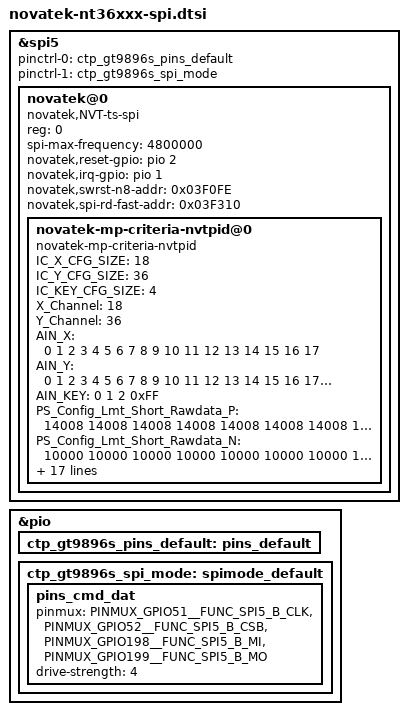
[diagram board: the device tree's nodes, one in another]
/*
 * Copyright (C) 2010 - 2018 Novatek, Inc.
 *
 * $Revision$
 * $Date$
 *
 * This program is free software; you can redistribute it and/or modify
 * it under the terms of the GNU General Public License as published by
 * the Free Software Foundation; either version 2 of the License, or
 * (at your option) any later version.
 *
 * This program is distributed in the hope that it will be useful, but WITHOUT
 * ANY WARRANTY; without even the implied warranty of MERCHANTABILITY or
 * FITNESS FOR A PARTICULAR PURPOSE.  See the GNU General Public License for
 * more details.
 *
 */

&spi5 {
	status = "okay";
	#address-cells = <1>;
	#size-cells = <0>;
	pinctrl-names = "default", "gt9896s_spi_mode";
	pinctrl-0 = <&ctp_gt9896s_pins_default>;
	pinctrl-1 = <&ctp_gt9896s_spi_mode>;
	/* Novatek device tree node */
	novatek@0 {
		compatible = "novatek,NVT-ts-spi";
		reg = <0>; //Same as CS ID
		status = "okay";
		//4800000,9600000,15000000,19200000
		spi-max-frequency = <4800000>;

		novatek,reset-gpio = <&pio 2 0x00>;
		novatek,irq-gpio = <&pio 1 0x00>;

		/* 525 */
		//novatek,swrst-n8-addr = <0x01F01A>;

		/* 672A, 525B, 675, 526 */
		novatek,swrst-n8-addr = <0x03F0FE>;
		novatek,spi-rd-fast-addr = <0x03F310>;

		/* MP */
		//novatek,mp-support-dt;

		novatek-mp-criteria-nvtpid@0 {
			#address-cells = <1>;
			#size-cells = <0>;
			compatible = "novatek-mp-criteria-nvtpid";

			/* MP Config */
			IC_X_CFG_SIZE = <18>;
			IC_Y_CFG_SIZE = <36>;
			IC_KEY_CFG_SIZE = <4>;
			X_Channel = <18>;
			Y_Channel = <36>;
			AIN_X = <0 1 2 3 4 5 6 7 8 9 10 11 12 13 14 15 16 17>;
			AIN_Y = <0 1 2 3 4 5 6 7 8 9 10 11 12 13 14 15 16 17
			18 19 20 21 22 23 24 25 26 27 28 29 30 31 32 33 34 35>;
			AIN_KEY = <0 1 2 0xFF>;

			/* MP Criteria */
			PS_Config_Lmt_Short_Rawdata_P =
			    <14008 14008 14008 14008 14008 14008 14008 14008 14008 14008 14008 14008
			    14008 14008 14008 14008 14008 14008 14008 14008 14008 14008 14008 14008
			    14008 14008 14008 14008 14008 14008 14008 14008 14008 14008 14008 14008
			    14008 14008 14008 14008 14008 14008 14008 14008 14008 14008 14008 14008
			    14008 14008 14008 14008 14008 14008 14008 14008 14008 14008 14008 14008
			    14008 14008 14008 14008 14008 14008 14008 14008 14008 14008 14008 14008
			    14008 14008 14008 14008 14008 14008 14008 14008 14008 14008 14008 14008
			    14008 14008 14008 14008 14008 14008 14008 14008 14008 14008 14008 14008
			    14008 14008 14008 14008 14008 14008 14008 14008 14008 14008 14008 14008
			    14008 14008 14008 14008 14008 14008 14008 14008 14008 14008 14008 14008
			    14008 14008 14008 14008 14008 14008 14008 14008 14008 14008 14008 14008
			    14008 14008 14008 14008 14008 14008 14008 14008 14008 14008 14008 14008
			    14008 14008 14008 14008 14008 14008 14008 14008 14008 14008 14008 14008
			    14008 14008 14008 14008 14008 14008 14008 14008 14008 14008 14008 14008
			    14008 14008 14008 14008 14008 14008 14008 14008 14008 14008 14008 14008
			    14008 14008 14008 14008 14008 14008 14008 14008 14008 14008 14008 14008
			    14008 14008 14008 14008 14008 14008 14008 14008 14008 14008 14008 14008
			    14008 14008 14008 14008 14008 14008 14008 14008 14008 14008 14008 14008
			    14008 14008 14008 14008 14008 14008 14008 14008 14008 14008 14008 14008
			    14008 14008 14008 14008 14008 14008 14008 14008 14008 14008 14008 14008
			    14008 14008 14008 14008 14008 14008 14008 14008 14008 14008 14008 14008
			    14008 14008 14008 14008 14008 14008 14008 14008 14008 14008 14008 14008
			    14008 14008 14008 14008 14008 14008 14008 14008 14008 14008 14008 14008
			    14008 14008 14008 14008 14008 14008 14008 14008 14008 14008 14008 14008
			    14008 14008 14008 14008 14008 14008 14008 14008 14008 14008 14008 14008
			    14008 14008 14008 14008 14008 14008 14008 14008 14008 14008 14008 14008
			    14008 14008 14008 14008 14008 14008 14008 14008 14008 14008 14008 14008
			    14008 14008 14008 14008 14008 14008 14008 14008 14008 14008 14008 14008
			    14008 14008 14008 14008 14008 14008 14008 14008 14008 14008 14008 14008
			    14008 14008 14008 14008 14008 14008 14008 14008 14008 14008 14008 14008
			    14008 14008 14008 14008 14008 14008 14008 14008 14008 14008 14008 14008
			    14008 14008 14008 14008 14008 14008 14008 14008 14008 14008 14008 14008
			    14008 14008 14008 14008 14008 14008 14008 14008 14008 14008 14008 14008
			    14008 14008 14008 14008 14008 14008 14008 14008 14008 14008 14008 14008
			    14008 14008 14008 14008 14008 14008 14008 14008 14008 14008 14008 14008
			    14008 14008 14008 14008 14008 14008 14008 14008 14008 14008 14008 14008
			    14008 14008 14008 14008 14008 14008 14008 14008 14008 14008 14008 14008
			    14008 14008 14008 14008 14008 14008 14008 14008 14008 14008 14008 14008
			    14008 14008 14008 14008 14008 14008 14008 14008 14008 14008 14008 14008
			    14008 14008 14008 14008 14008 14008 14008 14008 14008 14008 14008 14008
			    14008 14008 14008 14008 14008 14008 14008 14008 14008 14008 14008 14008
			    14008 14008 14008 14008 14008 14008 14008 14008 14008 14008 14008 14008
			    14008 14008 14008 14008 14008 14008 14008 14008 14008 14008 14008 14008
			    14008 14008 14008 14008 14008 14008 14008 14008 14008 14008 14008 14008
			    14008 14008 14008 14008 14008 14008 14008 14008 14008 14008 14008 14008
			    14008 14008 14008 14008 14008 14008 14008 14008 14008 14008 14008 14008
			    14008 14008 14008 14008 14008 14008 14008 14008 14008 14008 14008 14008
			    14008 14008 14008 14008 14008 14008 14008 14008 14008 14008 14008 14008
			    14008 14008 14008 14008 14008 14008 14008 14008 14008 14008 14008 14008
			    14008 14008 14008 14008 14008 14008 14008 14008 14008 14008 14008 14008
			    14008 14008 14008 14008 14008 14008 14008 14008 14008 14008 14008 14008
			    14008 14008 14008 14008 14008 14008 14008 14008 14008 14008 14008 14008
			    14008 14008 14008 14008 14008 14008 14008 14008 14008 14008 14008 14008
			    14008 14008 14008 14008 14008 14008 14008 14008 14008 14008 14008 14008
			    14008 14008 14008>;

			PS_Config_Lmt_Short_Rawdata_N =
			    <10000 10000 10000 10000 10000 10000 10000 10000 10000 10000 10000 10000
			    10000 10000 10000 10000 10000 10000 10000 10000 10000 10000 10000 10000
			    10000 10000 10000 10000 10000 10000 10000 10000 10000 10000 10000 10000
			    10000 10000 10000 10000 10000 10000 10000 10000 10000 10000 10000 10000
			    10000 10000 10000 10000 10000 10000 10000 10000 10000 10000 10000 10000
			    10000 10000 10000 10000 10000 10000 10000 10000 10000 10000 10000 10000
			    10000 10000 10000 10000 10000 10000 10000 10000 10000 10000 10000 10000
			    10000 10000 10000 10000 10000 10000 10000 10000 10000 10000 10000 10000
			    10000 10000 10000 10000 10000 10000 10000 10000 10000 10000 10000 10000
			    10000 10000 10000 10000 10000 10000 10000 10000 10000 10000 10000 10000
			    10000 10000 10000 10000 10000 10000 10000 10000 10000 10000 10000 10000
			    10000 10000 10000 10000 10000 10000 10000 10000 10000 10000 10000 10000
			    10000 10000 10000 10000 10000 10000 10000 10000 10000 10000 10000 10000
			    10000 10000 10000 10000 10000 10000 10000 10000 10000 10000 10000 10000
			    10000 10000 10000 10000 10000 10000 10000 10000 10000 10000 10000 10000
			    10000 10000 10000 10000 10000 10000 10000 10000 10000 10000 10000 10000
			    10000 10000 10000 10000 10000 10000 10000 10000 10000 10000 10000 10000
			    10000 10000 10000 10000 10000 10000 10000 10000 10000 10000 10000 10000
			    10000 10000 10000 10000 10000 10000 10000 10000 10000 10000 10000 10000
			    10000 10000 10000 10000 10000 10000 10000 10000 10000 10000 10000 10000
			    10000 10000 10000 10000 10000 10000 10000 10000 10000 10000 10000 10000
			    10000 10000 10000 10000 10000 10000 10000 10000 10000 10000 10000 10000
			    10000 10000 10000 10000 10000 10000 10000 10000 10000 10000 10000 10000
			    10000 10000 10000 10000 10000 10000 10000 10000 10000 10000 10000 10000
			    10000 10000 10000 10000 10000 10000 10000 10000 10000 10000 10000 10000
			    10000 10000 10000 10000 10000 10000 10000 10000 10000 10000 10000 10000
			    10000 10000 10000 10000 10000 10000 10000 10000 10000 10000 10000 10000
			    10000 10000 10000 10000 10000 10000 10000 10000 10000 10000 10000 10000
			    10000 10000 10000 10000 10000 10000 10000 10000 10000 10000 10000 10000
			    10000 10000 10000 10000 10000 10000 10000 10000 10000 10000 10000 10000
			    10000 10000 10000 10000 10000 10000 10000 10000 10000 10000 10000 10000
			    10000 10000 10000 10000 10000 10000 10000 10000 10000 10000 10000 10000
			    10000 10000 10000 10000 10000 10000 10000 10000 10000 10000 10000 10000
			    10000 10000 10000 10000 10000 10000 10000 10000 10000 10000 10000 10000
			    10000 10000 10000 10000 10000 10000 10000 10000 10000 10000 10000 10000
			    10000 10000 10000 10000 10000 10000 10000 10000 10000 10000 10000 10000
			    10000 10000 10000 10000 10000 10000 10000 10000 10000 10000 10000 10000
			    10000 10000 10000 10000 10000 10000 10000 10000 10000 10000 10000 10000
			    10000 10000 10000 10000 10000 10000 10000 10000 10000 10000 10000 10000
			    10000 10000 10000 10000 10000 10000 10000 10000 10000 10000 10000 10000
			    10000 10000 10000 10000 10000 10000 10000 10000 10000 10000 10000 10000
			    10000 10000 10000 10000 10000 10000 10000 10000 10000 10000 10000 10000
			    10000 10000 10000 10000 10000 10000 10000 10000 10000 10000 10000 10000
			    10000 10000 10000 10000 10000 10000 10000 10000 10000 10000 10000 10000
			    10000 10000 10000 10000 10000 10000 10000 10000 10000 10000 10000 10000
			    10000 10000 10000 10000 10000 10000 10000 10000 10000 10000 10000 10000
			    10000 10000 10000 10000 10000 10000 10000 10000 10000 10000 10000 10000
			    10000 10000 10000 10000 10000 10000 10000 10000 10000 10000 10000 10000
			    10000 10000 10000 10000 10000 10000 10000 10000 10000 10000 10000 10000
			    10000 10000 10000 10000 10000 10000 10000 10000 10000 10000 10000 10000
			    10000 10000 10000 10000 10000 10000 10000 10000 10000 10000 10000 10000
			    10000 10000 10000 10000 10000 10000 10000 10000 10000 10000 10000 10000
			    10000 10000 10000 10000 10000 10000 10000 10000 10000 10000 10000 10000
			    10000 10000 10000 10000 10000 10000 10000 10000 10000 10000 10000 10000
			    10000 10000 10000>;

			PS_Config_Lmt_Open_Rawdata_P =
			    <5120 5120 5120 5120 5120 5120 5120 5120 5120 5120 5120 5120 5120 5120
			    5120 5120 5120 5120 5120 5120 5120 5120 5120 5120 5120 5120 5120 5120
			    5120 5120 5120 5120 5120 5120 5120 5120 5120 5120 5120 5120 5120 5120
			    5120 5120 5120 5120 5120 5120 5120 5120 5120 5120 5120 5120 5120 5120
			    5120 5120 5120 5120 5120 5120 5120 5120 5120 5120 5120 5120 5120 5120
			    5120 5120 5120 5120 5120 5120 5120 5120 5120 5120 5120 5120 5120 5120
			    5120 5120 5120 5120 5120 5120 5120 5120 5120 5120 5120 5120 5120 5120
			    5120 5120 5120 5120 5120 5120 5120 5120 5120 5120 5120 5120 5120 5120
			    5120 5120 5120 5120 5120 5120 5120 5120 5120 5120 5120 5120 5120 5120
			    5120 5120 5120 5120 5120 5120 5120 5120 5120 5120 5120 5120 5120 5120
			    5120 5120 5120 5120 5120 5120 5120 5120 5120 5120 5120 5120 5120 5120
			    5120 5120 5120 5120 5120 5120 5120 5120 5120 5120 5120 5120 5120 5120
			    5120 5120 5120 5120 5120 5120 5120 5120 5120 5120 5120 5120 5120 5120
			    5120 5120 5120 5120 5120 5120 5120 5120 5120 5120 5120 5120 5120 5120
			    5120 5120 5120 5120 5120 5120 5120 5120 5120 5120 5120 5120 5120 5120
			    5120 5120 5120 5120 5120 5120 5120 5120 5120 5120 5120 5120 5120 5120
			    5120 5120 5120 5120 5120 5120 5120 5120 5120 5120 5120 5120 5120 5120
			    5120 5120 5120 5120 5120 5120 5120 5120 5120 5120 5120 5120 5120 5120
			    5120 5120 5120 5120 5120 5120 5120 5120 5120 5120 5120 5120 5120 5120
			    5120 5120 5120 5120 5120 5120 5120 5120 5120 5120 5120 5120 5120 5120
			    5120 5120 5120 5120 5120 5120 5120 5120 5120 5120 5120 5120 5120 5120
			    5120 5120 5120 5120 5120 5120 5120 5120 5120 5120 5120 5120 5120 5120
			    5120 5120 5120 5120 5120 5120 5120 5120 5120 5120 5120 5120 5120 5120
			    5120 5120 5120 5120 5120 5120 5120 5120 5120 5120 5120 5120 5120 5120
			    5120 5120 5120 5120 5120 5120 5120 5120 5120 5120 5120 5120 5120 5120
			    5120 5120 5120 5120 5120 5120 5120 5120 5120 5120 5120 5120 5120 5120
			    5120 5120 5120 5120 5120 5120 5120 5120 5120 5120 5120 5120 5120 5120
			    5120 5120 5120 5120 5120 5120 5120 5120 5120 5120 5120 5120 5120 5120
			    5120 5120 5120 5120 5120 5120 5120 5120 5120 5120 5120 5120 5120 5120
			    5120 5120 5120 5120 5120 5120 5120 5120 5120 5120 5120 5120 5120 5120
			    5120 5120 5120 5120 5120 5120 5120 5120 5120 5120 5120 5120 5120 5120
			    5120 5120 5120 5120 5120 5120 5120 5120 5120 5120 5120 5120 5120 5120
			    5120 5120 5120 5120 5120 5120 5120 5120 5120 5120 5120 5120 5120 5120
			    5120 5120 5120 5120 5120 5120 5120 5120 5120 5120 5120 5120 5120 5120
			    5120 5120 5120 5120 5120 5120 5120 5120 5120 5120 5120 5120 5120 5120
			    5120 5120 5120 5120 5120 5120 5120 5120 5120 5120 5120 5120 5120 5120
			    5120 5120 5120 5120 5120 5120 5120 5120 5120 5120 5120 5120 5120 5120
			    5120 5120 5120 5120 5120 5120 5120 5120 5120 5120 5120 5120 5120 5120
			    5120 5120 5120 5120 5120 5120 5120 5120 5120 5120 5120 5120 5120 5120
			    5120 5120 5120 5120 5120 5120 5120 5120 5120 5120 5120 5120 5120 5120
			    5120 5120 5120 5120 5120 5120 5120 5120 5120 5120 5120 5120 5120 5120
			    5120 5120 5120 5120 5120 5120 5120 5120 5120 5120 5120 5120 5120 5120
			    5120 5120 5120 5120 5120 5120 5120 5120 5120 5120 5120 5120 5120 5120
			    5120 5120 5120 5120 5120 5120 5120 5120 5120 5120 5120 5120 5120 5120
			    5120 5120 5120 5120 5120 5120 5120 5120 5120 5120 5120 5120 5120 5120
			    5120 5120 5120 5120 5120 5120 5120 5120 5120 5120 5120 5120 5120 5120
			    5120 5120 5120 5120 5120 5120 5120>;

			PS_Config_Lmt_Open_Rawdata_N =
			    <50 50 50 50 50 50 50 50 50 50 50 50 50 50 50 50 50 50 50 50 50 50 50 50
			    50 50 50 50 50 50 50 50 50 50 50 50 50 50 50 50 50 50 50 50 50 50 50 50
			    50 50 50 50 50 50 50 50 50 50 50 50 50 50 50 50 50 50 50 50 50 50 50 50
			    50 50 50 50 50 50 50 50 50 50 50 50 50 50 50 50 50 50 50 50 50 50 50 50
			    50 50 50 50 50 50 50 50 50 50 50 50 50 50 50 50 50 50 50 50 50 50 50 50
			    50 50 50 50 50 50 50 50 50 50 50 50 50 50 50 50 50 50 50 50 50 50 50 50
			    50 50 50 50 50 50 50 50 50 50 50 50 50 50 50 50 50 50 50 50 50 50 50 50
			    50 50 50 50 50 50 50 50 50 50 50 50 50 50 50 50 50 50 50 50 50 50 50 50
			    50 50 50 50 50 50 50 50 50 50 50 50 50 50 50 50 50 50 50 50 50 50 50 50
			    50 50 50 50 50 50 50 50 50 50 50 50 50 50 50 50 50 50 50 50 50 50 50 50
			    50 50 50 50 50 50 50 50 50 50 50 50 50 50 50 50 50 50 50 50 50 50 50 50
			    50 50 50 50 50 50 50 50 50 50 50 50 50 50 50 50 50 50 50 50 50 50 50 50
			    50 50 50 50 50 50 50 50 50 50 50 50 50 50 50 50 50 50 50 50 50 50 50 50
			    50 50 50 50 50 50 50 50 50 50 50 50 50 50 50 50 50 50 50 50 50 50 50 50
			    50 50 50 50 50 50 50 50 50 50 50 50 50 50 50 50 50 50 50 50 50 50 50 50
			    50 50 50 50 50 50 50 50 50 50 50 50 50 50 50 50 50 50 50 50 50 50 50 50
			    50 50 50 50 50 50 50 50 50 50 50 50 50 50 50 50 50 50 50 50 50 50 50 50
			    50 50 50 50 50 50 50 50 50 50 50 50 50 50 50 50 50 50 50 50 50 50 50 50
			    50 50 50 50 50 50 50 50 50 50 50 50 50 50 50 50 50 50 50 50 50 50 50 50
			    50 50 50 50 50 50 50 50 50 50 50 50 50 50 50 50 50 50 50 50 50 50 50 50
			    50 50 50 50 50 50 50 50 50 50 50 50 50 50 50 50 50 50 50 50 50 50 50 50
			    50 50 50 50 50 50 50 50 50 50 50 50 50 50 50 50 50 50 50 50 50 50 50 50
			    50 50 50 50 50 50 50 50 50 50 50 50 50 50 50 50 50 50 50 50 50 50 50 50
			    50 50 50 50 50 50 50 50 50 50 50 50 50 50 50 50 50 50 50 50 50 50 50 50
			    50 50 50 50 50 50 50 50 50 50 50 50 50 50 50 50 50 50 50 50 50 50 50 50
			    50 50 50 50 50 50 50 50 50 50 50 50 50 50 50 50 50 50 50 50 50 50 50 50
			    50 50 50 50 50 50 50 50 50 50 50 50 50 50 50 50 50 50 50 50 50 50 50 50
			    50 50 50>;

			PS_Config_Lmt_FW_Rawdata_P =
			    <2560 2560 2560 2560 2560 2560 2560 2560 2560 2560 2560 2560 2560 2560
			    2560 2560 2560 2560 2560 2560 2560 2560 2560 2560 2560 2560 2560 2560
			    2560 2560 2560 2560 2560 2560 2560 2560 2560 2560 2560 2560 2560 2560
			    2560 2560 2560 2560 2560 2560 2560 2560 2560 2560 2560 2560 2560 2560
			    2560 2560 2560 2560 2560 2560 2560 2560 2560 2560 2560 2560 2560 2560
			    2560 2560 2560 2560 2560 2560 2560 2560 2560 2560 2560 2560 2560 2560
			    2560 2560 2560 2560 2560 2560 2560 2560 2560 2560 2560 2560 2560 2560
			    2560 2560 2560 2560 2560 2560 2560 2560 2560 2560 2560 2560 2560 2560
			    2560 2560 2560 2560 2560 2560 2560 2560 2560 2560 2560 2560 2560 2560
			    2560 2560 2560 2560 2560 2560 2560 2560 2560 2560 2560 2560 2560 2560
			    2560 2560 2560 2560 2560 2560 2560 2560 2560 2560 2560 2560 2560 2560
			    2560 2560 2560 2560 2560 2560 2560 2560 2560 2560 2560 2560 2560 2560
			    2560 2560 2560 2560 2560 2560 2560 2560 2560 2560 2560 2560 2560 2560
			    2560 2560 2560 2560 2560 2560 2560 2560 2560 2560 2560 2560 2560 2560
			    2560 2560 2560 2560 2560 2560 2560 2560 2560 2560 2560 2560 2560 2560
			    2560 2560 2560 2560 2560 2560 2560 2560 2560 2560 2560 2560 2560 2560
			    2560 2560 2560 2560 2560 2560 2560 2560 2560 2560 2560 2560 2560 2560
			    2560 2560 2560 2560 2560 2560 2560 2560 2560 2560 2560 2560 2560 2560
			    2560 2560 2560 2560 2560 2560 2560 2560 2560 2560 2560 2560 2560 2560
			    2560 2560 2560 2560 2560 2560 2560 2560 2560 2560 2560 2560 2560 2560
			    2560 2560 2560 2560 2560 2560 2560 2560 2560 2560 2560 2560 2560 2560
			    2560 2560 2560 2560 2560 2560 2560 2560 2560 2560 2560 2560 2560 2560
			    2560 2560 2560 2560 2560 2560 2560 2560 2560 2560 2560 2560 2560 2560
			    2560 2560 2560 2560 2560 2560 2560 2560 2560 2560 2560 2560 2560 2560
			    2560 2560 2560 2560 2560 2560 2560 2560 2560 2560 2560 2560 2560 2560
			    2560 2560 2560 2560 2560 2560 2560 2560 2560 2560 2560 2560 2560 2560
			    2560 2560 2560 2560 2560 2560 2560 2560 2560 2560 2560 2560 2560 2560
			    2560 2560 2560 2560 2560 2560 2560 2560 2560 2560 2560 2560 2560 2560
			    2560 2560 2560 2560 2560 2560 2560 2560 2560 2560 2560 2560 2560 2560
			    2560 2560 2560 2560 2560 2560 2560 2560 2560 2560 2560 2560 2560 2560
			    2560 2560 2560 2560 2560 2560 2560 2560 2560 2560 2560 2560 2560 2560
			    2560 2560 2560 2560 2560 2560 2560 2560 2560 2560 2560 2560 2560 2560
			    2560 2560 2560 2560 2560 2560 2560 2560 2560 2560 2560 2560 2560 2560
			    2560 2560 2560 2560 2560 2560 2560 2560 2560 2560 2560 2560 2560 2560
			    2560 2560 2560 2560 2560 2560 2560 2560 2560 2560 2560 2560 2560 2560
			    2560 2560 2560 2560 2560 2560 2560 2560 2560 2560 2560 2560 2560 2560
			    2560 2560 2560 2560 2560 2560 2560 2560 2560 2560 2560 2560 2560 2560
			    2560 2560 2560 2560 2560 2560 2560 2560 2560 2560 2560 2560 2560 2560
			    2560 2560 2560 2560 2560 2560 2560 2560 2560 2560 2560 2560 2560 2560
			    2560 2560 2560 2560 2560 2560 2560 2560 2560 2560 2560 2560 2560 2560
			    2560 2560 2560 2560 2560 2560 2560 2560 2560 2560 2560 2560 2560 2560
			    2560 2560 2560 2560 2560 2560 2560 2560 2560 2560 2560 2560 2560 2560
			    2560 2560 2560 2560 2560 2560 2560 2560 2560 2560 2560 2560 2560 2560
			    2560 2560 2560 2560 2560 2560 2560 2560 2560 2560 2560 2560 2560 2560
			    2560 2560 2560 2560 2560 2560 2560 2560 2560 2560 2560 2560 2560 2560
			    2560 2560 2560 2560 2560 2560 2560 2560 2560 2560 2560 2560 2560 2560
			    2560 2560 2560 2560 2560 2560 2560>;

			PS_Config_Lmt_FW_Rawdata_N =
			    <240 240 240 240 240 240 240 240 240 240 240 240 240 240 240 240 240 240
			    240 240 240 240 240 240 240 240 240 240 240 240 240 240 240 240 240 240
			    240 240 240 240 240 240 240 240 240 240 240 240 240 240 240 240 240 240
			    240 240 240 240 240 240 240 240 240 240 240 240 240 240 240 240 240 240
			    240 240 240 240 240 240 240 240 240 240 240 240 240 240 240 240 240 240
			    240 240 240 240 240 240 240 240 240 240 240 240 240 240 240 240 240 240
			    240 240 240 240 240 240 240 240 240 240 240 240 240 240 240 240 240 240
			    240 240 240 240 240 240 240 240 240 240 240 240 240 240 240 240 240 240
			    240 240 240 240 240 240 240 240 240 240 240 240 240 240 240 240 240 240
			    240 240 240 240 240 240 240 240 240 240 240 240 240 240 240 240 240 240
			    240 240 240 240 240 240 240 240 240 240 240 240 240 240 240 240 240 240
			    240 240 240 240 240 240 240 240 240 240 240 240 240 240 240 240 240 240
			    240 240 240 240 240 240 240 240 240 240 240 240 240 240 240 240 240 240
			    240 240 240 240 240 240 240 240 240 240 240 240 240 240 240 240 240 240
			    240 240 240 240 240 240 240 240 240 240 240 240 240 240 240 240 240 240
			    240 240 240 240 240 240 240 240 240 240 240 240 240 240 240 240 240 240
			    240 240 240 240 240 240 240 240 240 240 240 240 240 240 240 240 240 240
			    240 240 240 240 240 240 240 240 240 240 240 240 240 240 240 240 240 240
			    240 240 240 240 240 240 240 240 240 240 240 240 240 240 240 240 240 240
			    240 240 240 240 240 240 240 240 240 240 240 240 240 240 240 240 240 240
			    240 240 240 240 240 240 240 240 240 240 240 240 240 240 240 240 240 240
			    240 240 240 240 240 240 240 240 240 240 240 240 240 240 240 240 240 240
			    240 240 240 240 240 240 240 240 240 240 240 240 240 240 240 240 240 240
			    240 240 240 240 240 240 240 240 240 240 240 240 240 240 240 240 240 240
			    240 240 240 240 240 240 240 240 240 240 240 240 240 240 240 240 240 240
			    240 240 240 240 240 240 240 240 240 240 240 240 240 240 240 240 240 240
			    240 240 240 240 240 240 240 240 240 240 240 240 240 240 240 240 240 240
			    240 240 240 240 240 240 240 240 240 240 240 240 240 240 240 240 240 240
			    240 240 240 240 240 240 240 240 240 240 240 240 240 240 240 240 240 240
			    240 240 240 240 240 240 240 240 240 240 240 240 240 240 240 240 240 240
			    240 240 240 240 240 240 240 240 240 240 240 240 240 240 240 240 240 240
			    240 240 240 240 240 240 240 240 240 240 240 240 240 240 240 240 240 240
			    240 240 240 240 240 240 240 240 240 240 240 240 240 240 240 240 240 240
			    240 240 240 240 240 240 240 240 240 240 240 240 240 240 240 240 240 240
			    240 240 240 240 240 240 240 240 240 240 240 240 240 240 240 240 240 240
			    240 240 240 240 240 240 240 240 240 240 240 240 240 240 240 240 240 240
			    240 240 240>;

			PS_Config_Lmt_FW_CC_P =
			    <314 314 314 314 314 314 314 314 314 314 314 314 314 314 314 314 314 314
			    314 314 314 314 314 314 314 314 314 314 314 314 314 314 314 314 314 314
			    314 314 314 314 314 314 314 314 314 314 314 314 314 314 314 314 314 314
			    314 314 314 314 314 314 314 314 314 314 314 314 314 314 314 314 314 314
			    314 314 314 314 314 314 314 314 314 314 314 314 314 314 314 314 314 314
			    314 314 314 314 314 314 314 314 314 314 314 314 314 314 314 314 314 314
			    314 314 314 314 314 314 314 314 314 314 314 314 314 314 314 314 314 314
			    314 314 314 314 314 314 314 314 314 314 314 314 314 314 314 314 314 314
			    314 314 314 314 314 314 314 314 314 314 314 314 314 314 314 314 314 314
			    314 314 314 314 314 314 314 314 314 314 314 314 314 314 314 314 314 314
			    314 314 314 314 314 314 314 314 314 314 314 314 314 314 314 314 314 314
			    314 314 314 314 314 314 314 314 314 314 314 314 314 314 314 314 314 314
			    314 314 314 314 314 314 314 314 314 314 314 314 314 314 314 314 314 314
			    314 314 314 314 314 314 314 314 314 314 314 314 314 314 314 314 314 314
			    314 314 314 314 314 314 314 314 314 314 314 314 314 314 314 314 314 314
			    314 314 314 314 314 314 314 314 314 314 314 314 314 314 314 314 314 314
			    314 314 314 314 314 314 314 314 314 314 314 314 314 314 314 314 314 314
			    314 314 314 314 314 314 314 314 314 314 314 314 314 314 314 314 314 314
			    314 314 314 314 314 314 314 314 314 314 314 314 314 314 314 314 314 314
			    314 314 314 314 314 314 314 314 314 314 314 314 314 314 314 314 314 314
			    314 314 314 314 314 314 314 314 314 314 314 314 314 314 314 314 314 314
			    314 314 314 314 314 314 314 314 314 314 314 314 314 314 314 314 314 314
			    314 314 314 314 314 314 314 314 314 314 314 314 314 314 314 314 314 314
			    314 314 314 314 314 314 314 314 314 314 314 314 314 314 314 314 314 314
			    314 314 314 314 314 314 314 314 314 314 314 314 314 314 314 314 314 314
			    314 314 314 314 314 314 314 314 314 314 314 314 314 314 314 314 314 314
			    314 314 314 314 314 314 314 314 314 314 314 314 314 314 314 314 314 314
			    314 314 314 314 314 314 314 314 314 314 314 314 314 314 314 314 314 314
			    314 314 314 314 314 314 314 314 314 314 314 314 314 314 314 314 314 314
			    314 314 314 314 314 314 314 314 314 314 314 314 314 314 314 314 314 314
			    314 314 314 314 314 314 314 314 314 314 314 314 314 314 314 314 314 314
			    314 314 314 314 314 314 314 314 314 314 314 314 314 314 314 314 314 314
			    314 314 314 314 314 314 314 314 314 314 314 314 314 314 314 314 314 314
			    314 314 314 314 314 314 314 314 314 314 314 314 314 314 314 314 314 314
			    314 314 314 314 314 314 314 314 314 314 314 314 314 314 314 314 314 314
			    314 314 314 314 314 314 314 314 314 314 314 314 314 314 314 314 314 314
			    314 314 314>;

			PS_Config_Lmt_FW_CC_N = <0 0 0 0 0 0 0 0 0 0 0 0 0 0 0 0 0 0
			    0 0 0 0 0 0 0 0 0 0 0 0 0 0 0 0 0 0
			    0 0 0 0 0 0 0 0 0 0 0 0 0 0 0 0 0 0
			    0 0 0 0 0 0 0 0 0 0 0 0 0 0 0 0 0 0
			    0 0 0 0 0 0 0 0 0 0 0 0 0 0 0 0 0 0
			    0 0 0 0 0 0 0 0 0 0 0 0 0 0 0 0 0 0
			    0 0 0 0 0 0 0 0 0 0 0 0 0 0 0 0 0 0
			    0 0 0 0 0 0 0 0 0 0 0 0 0 0 0 0 0 0
			    0 0 0 0 0 0 0 0 0 0 0 0 0 0 0 0 0 0
			    0 0 0 0 0 0 0 0 0 0 0 0 0 0 0 0 0 0
			    0 0 0 0 0 0 0 0 0 0 0 0 0 0 0 0 0 0
			    0 0 0 0 0 0 0 0 0 0 0 0 0 0 0 0 0 0
			    0 0 0 0 0 0 0 0 0 0 0 0 0 0 0 0 0 0
			    0 0 0 0 0 0 0 0 0 0 0 0 0 0 0 0 0 0
			    0 0 0 0 0 0 0 0 0 0 0 0 0 0 0 0 0 0
			    0 0 0 0 0 0 0 0 0 0 0 0 0 0 0 0 0 0
			    0 0 0 0 0 0 0 0 0 0 0 0 0 0 0 0 0 0
			    0 0 0 0 0 0 0 0 0 0 0 0 0 0 0 0 0 0
			    0 0 0 0 0 0 0 0 0 0 0 0 0 0 0 0 0 0
			    0 0 0 0 0 0 0 0 0 0 0 0 0 0 0 0 0 0
			    0 0 0 0 0 0 0 0 0 0 0 0 0 0 0 0 0 0
			    0 0 0 0 0 0 0 0 0 0 0 0 0 0 0 0 0 0
			    0 0 0 0 0 0 0 0 0 0 0 0 0 0 0 0 0 0
			    0 0 0 0 0 0 0 0 0 0 0 0 0 0 0 0 0 0
			    0 0 0 0 0 0 0 0 0 0 0 0 0 0 0 0 0 0
			    0 0 0 0 0 0 0 0 0 0 0 0 0 0 0 0 0 0
			    0 0 0 0 0 0 0 0 0 0 0 0 0 0 0 0 0 0
			    0 0 0 0 0 0 0 0 0 0 0 0 0 0 0 0 0 0
			    0 0 0 0 0 0 0 0 0 0 0 0 0 0 0 0 0 0
			    0 0 0 0 0 0 0 0 0 0 0 0 0 0 0 0 0 0
			    0 0 0 0 0 0 0 0 0 0 0 0 0 0 0 0 0 0
			    0 0 0 0 0 0 0 0 0 0 0 0 0 0 0 0 0 0
			    0 0 0 0 0 0 0 0 0 0 0 0 0 0 0 0 0 0
			    0 0 0 0 0 0 0 0 0 0 0 0 0 0 0 0 0 0
			    0 0 0 0 0 0 0 0 0 0 0 0 0 0 0 0 0 0
			    0 0 0 0 0 0 0 0 0 0 0 0 0 0 0 0 0 0 0 0 0>;

			PS_Config_Lmt_FW_Diff_P =
			    <75 75 75 75 75 75 75 75 75 75 75 75 75 75 75 75 75 75 75 75 75 75 75 75
			    75 75 75 75 75 75 75 75 75 75 75 75 75 75 75 75 75 75 75 75 75 75 75 75
			    75 75 75 75 75 75 75 75 75 75 75 75 75 75 75 75 75 75 75 75 75 75 75 75
			    75 75 75 75 75 75 75 75 75 75 75 75 75 75 75 75 75 75 75 75 75 75 75 75
			    75 75 75 75 75 75 75 75 75 75 75 75 75 75 75 75 75 75 75 75 75 75 75 75
			    75 75 75 75 75 75 75 75 75 75 75 75 75 75 75 75 75 75 75 75 75 75 75 75
			    75 75 75 75 75 75 75 75 75 75 75 75 75 75 75 75 75 75 75 75 75 75 75 75
			    75 75 75 75 75 75 75 75 75 75 75 75 75 75 75 75 75 75 75 75 75 75 75 75
			    75 75 75 75 75 75 75 75 75 75 75 75 75 75 75 75 75 75 75 75 75 75 75 75
			    75 75 75 75 75 75 75 75 75 75 75 75 75 75 75 75 75 75 75 75 75 75 75 75
			    75 75 75 75 75 75 75 75 75 75 75 75 75 75 75 75 75 75 75 75 75 75 75 75
			    75 75 75 75 75 75 75 75 75 75 75 75 75 75 75 75 75 75 75 75 75 75 75 75
			    75 75 75 75 75 75 75 75 75 75 75 75 75 75 75 75 75 75 75 75 75 75 75 75
			    75 75 75 75 75 75 75 75 75 75 75 75 75 75 75 75 75 75 75 75 75 75 75 75
			    75 75 75 75 75 75 75 75 75 75 75 75 75 75 75 75 75 75 75 75 75 75 75 75
			    75 75 75 75 75 75 75 75 75 75 75 75 75 75 75 75 75 75 75 75 75 75 75 75
			    75 75 75 75 75 75 75 75 75 75 75 75 75 75 75 75 75 75 75 75 75 75 75 75
			    75 75 75 75 75 75 75 75 75 75 75 75 75 75 75 75 75 75 75 75 75 75 75 75
			    75 75 75 75 75 75 75 75 75 75 75 75 75 75 75 75 75 75 75 75 75 75 75 75
			    75 75 75 75 75 75 75 75 75 75 75 75 75 75 75 75 75 75 75 75 75 75 75 75
			    75 75 75 75 75 75 75 75 75 75 75 75 75 75 75 75 75 75 75 75 75 75 75 75
			    75 75 75 75 75 75 75 75 75 75 75 75 75 75 75 75 75 75 75 75 75 75 75 75
			    75 75 75 75 75 75 75 75 75 75 75 75 75 75 75 75 75 75 75 75 75 75 75 75
			    75 75 75 75 75 75 75 75 75 75 75 75 75 75 75 75 75 75 75 75 75 75 75 75
			    75 75 75 75 75 75 75 75 75 75 75 75 75 75 75 75 75 75 75 75 75 75 75 75
			    75 75 75 75 75 75 75 75 75 75 75 75 75 75 75 75 75 75 75 75 75 75 75 75
			    75 75 75 75 75 75 75 75 75 75 75 75 75 75 75 75 75 75 75 75 75 75 75 75
			    75 75 75>;

			PS_Config_Lmt_FW_Diff_N = <
			    (-75) (-75) (-75) (-75) (-75) (-75) (-75) (-75) (-75) (-75) (-75) (-75)
			    (-75) (-75) (-75) (-75) (-75) (-75)
			    (-75) (-75) (-75) (-75) (-75) (-75) (-75) (-75) (-75) (-75) (-75) (-75)
			    (-75) (-75) (-75) (-75) (-75) (-75)
			    (-75) (-75) (-75) (-75) (-75) (-75) (-75) (-75) (-75) (-75) (-75) (-75)
			    (-75) (-75) (-75) (-75) (-75) (-75)
			    (-75) (-75) (-75) (-75) (-75) (-75) (-75) (-75) (-75) (-75) (-75) (-75)
			    (-75) (-75) (-75) (-75) (-75) (-75)
			    (-75) (-75) (-75) (-75) (-75) (-75) (-75) (-75) (-75) (-75) (-75) (-75)
			    (-75) (-75) (-75) (-75) (-75) (-75)
			    (-75) (-75) (-75) (-75) (-75) (-75) (-75) (-75) (-75) (-75) (-75) (-75)
			    (-75) (-75) (-75) (-75) (-75) (-75)
			    (-75) (-75) (-75) (-75) (-75) (-75) (-75) (-75) (-75) (-75) (-75) (-75)
			    (-75) (-75) (-75) (-75) (-75) (-75)
			    (-75) (-75) (-75) (-75) (-75) (-75) (-75) (-75) (-75) (-75) (-75) (-75)
			    (-75) (-75) (-75) (-75) (-75) (-75)
			    (-75) (-75) (-75) (-75) (-75) (-75) (-75) (-75) (-75) (-75) (-75) (-75)
			    (-75) (-75) (-75) (-75) (-75) (-75)
			    (-75) (-75) (-75) (-75) (-75) (-75) (-75) (-75) (-75) (-75) (-75) (-75)
			    (-75) (-75) (-75) (-75) (-75) (-75)
			    (-75) (-75) (-75) (-75) (-75) (-75) (-75) (-75) (-75) (-75) (-75) (-75)
			    (-75) (-75) (-75) (-75) (-75) (-75)
			    (-75) (-75) (-75) (-75) (-75) (-75) (-75) (-75) (-75) (-75) (-75) (-75)
			    (-75) (-75) (-75) (-75) (-75) (-75)
			    (-75) (-75) (-75) (-75) (-75) (-75) (-75) (-75) (-75) (-75) (-75) (-75)
			    (-75) (-75) (-75) (-75) (-75) (-75)
			    (-75) (-75) (-75) (-75) (-75) (-75) (-75) (-75) (-75) (-75) (-75) (-75)
			    (-75) (-75) (-75) (-75) (-75) (-75)
			    (-75) (-75) (-75) (-75) (-75) (-75) (-75) (-75) (-75) (-75) (-75) (-75)
			    (-75) (-75) (-75) (-75) (-75) (-75)
			    (-75) (-75) (-75) (-75) (-75) (-75) (-75) (-75) (-75) (-75) (-75) (-75)
			    (-75) (-75) (-75) (-75) (-75) (-75)
			    (-75) (-75) (-75) (-75) (-75) (-75) (-75) (-75) (-75) (-75) (-75) (-75)
			    (-75) (-75) (-75) (-75) (-75) (-75)
			    (-75) (-75) (-75) (-75) (-75) (-75) (-75) (-75) (-75) (-75) (-75) (-75)
			    (-75) (-75) (-75) (-75) (-75) (-75)
			    (-75) (-75) (-75) (-75) (-75) (-75) (-75) (-75) (-75) (-75) (-75) (-75)
			    (-75) (-75) (-75) (-75) (-75) (-75)
			    (-75) (-75) (-75) (-75) (-75) (-75) (-75) (-75) (-75) (-75) (-75) (-75)
			    (-75) (-75) (-75) (-75) (-75) (-75)
			    (-75) (-75) (-75) (-75) (-75) (-75) (-75) (-75) (-75) (-75) (-75) (-75)
			    (-75) (-75) (-75) (-75) (-75) (-75)
			    (-75) (-75) (-75) (-75) (-75) (-75) (-75) (-75) (-75) (-75) (-75) (-75)
			    (-75) (-75) (-75) (-75) (-75) (-75)
			    (-75) (-75) (-75) (-75) (-75) (-75) (-75) (-75) (-75) (-75) (-75) (-75)
			    (-75) (-75) (-75) (-75) (-75) (-75)
			    (-75) (-75) (-75) (-75) (-75) (-75) (-75) (-75) (-75) (-75) (-75) (-75)
			    (-75) (-75) (-75) (-75) (-75) (-75)
			    (-75) (-75) (-75) (-75) (-75) (-75) (-75) (-75) (-75) (-75) (-75) (-75)
			    (-75) (-75) (-75) (-75) (-75) (-75)
			    (-75) (-75) (-75) (-75) (-75) (-75) (-75) (-75) (-75) (-75) (-75) (-75)
			    (-75) (-75) (-75) (-75) (-75) (-75)
			    (-75) (-75) (-75) (-75) (-75) (-75) (-75) (-75) (-75) (-75) (-75) (-75)
			    (-75) (-75) (-75) (-75) (-75) (-75)
			    (-75) (-75) (-75) (-75) (-75) (-75) (-75) (-75) (-75) (-75) (-75) (-75)
			    (-75) (-75) (-75) (-75) (-75) (-75)
			    (-75) (-75) (-75) (-75) (-75) (-75) (-75) (-75) (-75) (-75) (-75) (-75)
			    (-75) (-75) (-75) (-75) (-75) (-75)
			    (-75) (-75) (-75) (-75) (-75) (-75) (-75) (-75) (-75) (-75) (-75) (-75)
			    (-75) (-75) (-75) (-75) (-75) (-75)
			    (-75) (-75) (-75) (-75) (-75) (-75) (-75) (-75) (-75) (-75) (-75) (-75)
			    (-75) (-75) (-75) (-75) (-75) (-75)
			    (-75) (-75) (-75) (-75) (-75) (-75) (-75) (-75) (-75) (-75) (-75) (-75)
			    (-75) (-75) (-75) (-75) (-75) (-75)
			    (-75) (-75) (-75) (-75) (-75) (-75) (-75) (-75) (-75) (-75) (-75) (-75)
			    (-75) (-75) (-75) (-75) (-75) (-75)
			    (-75) (-75) (-75) (-75) (-75) (-75) (-75) (-75) (-75) (-75) (-75) (-75)
			    (-75) (-75) (-75) (-75) (-75) (-75)
			    (-75) (-75) (-75) (-75) (-75) (-75) (-75) (-75) (-75) (-75) (-75) (-75)
			    (-75) (-75) (-75) (-75) (-75) (-75)
			    (-75) (-75) (-75) (-75) (-75) (-75) (-75) (-75) (-75) (-75) (-75) (-75)
			    (-75) (-75) (-75) (-75) (-75) (-75)
			    (-75) (-75) (-75)>;

			PS_Config_Diff_Test_Frame = <50>;
		};
	};
};

&pio {
	ctp_gt9896s_pins_default: pins_default {
	};
	ctp_gt9896s_spi_mode: spimode_default {
		pins_cmd_dat {
			pinmux = <PINMUX_GPIO51__FUNC_SPI5_B_CLK>,
				<PINMUX_GPIO52__FUNC_SPI5_B_CSB>,
				<PINMUX_GPIO198__FUNC_SPI5_B_MI>,
				<PINMUX_GPIO199__FUNC_SPI5_B_MO>;
			drive-strength = <4>;
		};
	};
};
